# VENC register map
Vendor: Texas Instruments
Peripheral module from a debugger description file (folder DM50x).
Registers are 32-bit, access per field, reset 0x0 unless marked. A register's access mark holds for its fields unless they carry their own. Offsets are as the file gives them; lines under a group give offsets from that group; [hi:lo] are bit positions; {n}, {i} and the like mark numbered series; 'fields as' and 'values as' point back to an identical list; <NAME> marks a mode.

## VENC
0x00 VENC_REV_ID ro reset not defined — Revision ID for the encoder
  [31:0] REVISION — IP Revision
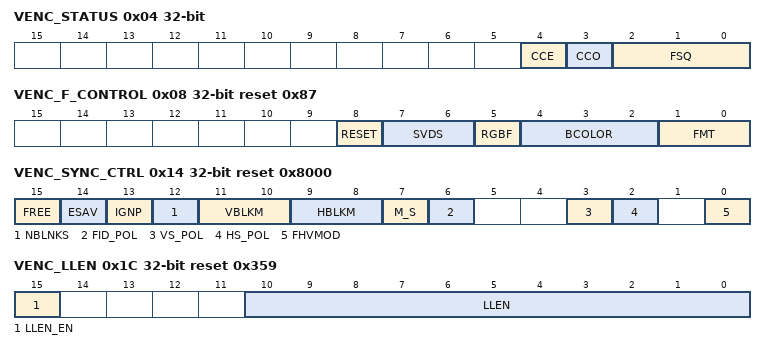
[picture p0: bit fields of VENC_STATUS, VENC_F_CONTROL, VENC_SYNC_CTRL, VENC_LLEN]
0x04 VENC_STATUS ro — STATUS
  [4] CCE — Closed Caption Status for Even Field. This bit is set immediately after the data in registers LINE21_E0 and LINE21_E1 have been encoded to closed caption. This bit is reset when both of these registers are written.
  [3] CCO — Closed Caption Status for Odd Field. This bit is set immediately after the data in registers LINE21_O0 and LINE21_O1 have been encoded to closed caption. This bit is reset when both of these registers are written.
  [2:0] FSQ — Field Sequence ID. For PAL, all three FSQ[2:0] are used whereas for NTSC only FSQ[1:0] is meaningful. Furthermore, FSQ[0] represents ODD field when it is '0' and EVEN field when it is '1'.
    0=ODD_field; 1=EVEN_field
0x08 VENC_F_CONTROL reset 0x87 — This register specifies the input video source and format
  [8] RESET rw — RESET the encoder
    0=No_effect; 1=Reset the encoder, after reset, this bit is automatically set to zero
  [7:6] SVDS rw — Select Video Data Source.
    0=Use_external_video_source; 1=Use_internal_Color_BAR; 2=Use_background_color
  [5] RGBF rw — RGB /YCrCb input coding range
    0=RGB_0 (The input RGB data are in binary format with coding range 0-255 The input YCrCb data are in binary format with coding range 0-255); 1=RGB_ITU-601_1 (The input RGB data are in binary format with coding range 16-235 The input YCrCb data are in binary format conforming to ITU-601 standard)
  [4:2] BCOLOR rw — Background color select
  [1:0] FMT rw — These two bits specify the video input data stream format and timing
    0=24-bit_4:4:4_RGB; 1=24-bit_4:4:4; 2=16-bit_4:2:2; 3=8-bit_ITU-R_656_4:2:2
0x10 VENC_VIDOUT_CTRL — Encoder output clock
  [0] MHZ_27_54 rw
    0=54_MHz,_4x_oversampling; 1=27MHz, 2x oversampling, the last 2x oversampling filter bypassed
0x14 VENC_SYNC_CTRL reset 0x8000 — SYNC Control register
  [15] FREE rw — Free running
    0=Free_running_disabled; 1=HSYNC_VSYNC_1 (Free running enabled. HSYNC and VSYNC are ignored)
  [14] ESAV rw — Enable to detect F and V bits only on EAV in ITU-R 656 input mode
    0=F_V_EAV_SAV_0 (Detection of F and V bits on both EAV and SAV); 1=Detection_of_F_and_V_bits_only_on_EAV
  [13] IGNP rw — Ignore protection bits in ITU-R 656 input mode
    0=Protection_bits_are_not_ignored; 1=Protection_bits_are_ignored
  [12] NBLNKS rw — Blank shaping
    0=Blank_shaping_enabled; 1=Blank_shaping_disabled
  [11:10] VBLKM rw — Vertical blanking mode
    0=Internal_default_blanking; 1=AND_FAL_LAL_1 (Internal default blanking AND internal programmable blanking defined by FAL and LAL)
  [9:8] HBLKM rw — Horizontal blanking mode
    0=Internal_default_blanking; 1=SAVID_EAVID_1 (Internal programmable blanking defined by SAVID and EAVID); 2=External_blanking_defined_by_AVID
  [7] M_S rw — Encoder is master or slave of external sync
    0=FID_AVID._0 (Sync master. Encoder outputs Vsync, Hsync, FID and AVID.); 1=FID_AVID._1 (Sync slave. Encoder is synchronized to external Vsync, Hsync, FID and AVID.)
  [6] FID_POL rw — FID output polarity
    0=ODD_field_=_'0'_EVEN_field_=_'1'; 1=ODD_field_=_'1'_EVEN_field_=_'0'
  [3] VS_POL rw — VS input polarity
    0=VS_is_active_high; 1=VS_is_active_low
  [2] HS_POL rw — HS input polarity
    0=HS_is_active_high; 1=HS_is_active_low
  [0] FHVMOD rw — FID extracted from external FID or HSYNC and VSYNC
    0=External_FID; 1=Extracted_from_HSYNC_and_VSYNC
0x1C VENC_LLEN reset 0x359 — LLEN
  [15] LLEN_EN rw
    0=disable; 1=enable
  [10:0] LLEN rw — LLEN[10:0] Line length or total number of pixels in a scan line including active video and blanking. Total number of pixels in a scan line = LLEN NOTE: A write to bit 11 of this bit field is illegal.
0x20 VENC_FLENS reset 0x20C — FLENS
  [10:0] FLENS rw — The frame length or total number of lines in a frame including active video and blanking from the source image. Total number of lines in a frame from the source image = FLENS + 1
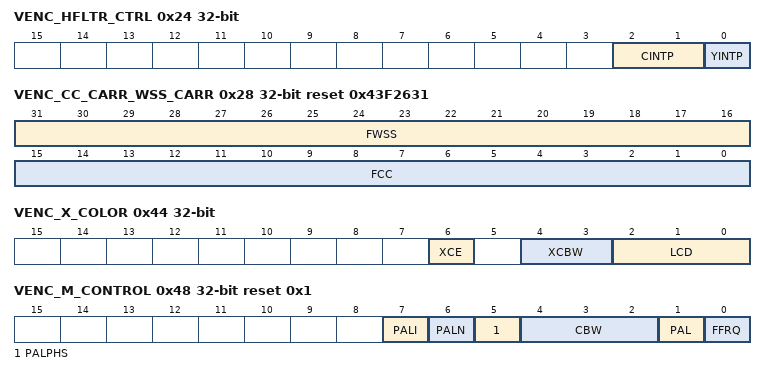
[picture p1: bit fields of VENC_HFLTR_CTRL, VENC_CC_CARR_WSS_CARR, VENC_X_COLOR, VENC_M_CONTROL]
0x24 VENC_HFLTR_CTRL — HFLTR_CTRL
  [2:1] CINTP rw — Chrominance interpolation filter control
    0=The chrominance interpolation filter is enabled; 1=The first section of the chrominance interpolation filter is bypassed; 2=The second section of the chrominance interpolation filter is bypassed; 3=Both sections of the filter are bypassed
  [0] YINTP rw — Luminance interpolation filter control
    0=The luminance interpolation filter is enabled; 1=The luminance interpolation filter is bypassed
0x28 VENC_CC_CARR_WSS_CARR rw reset 0x43F2631 — Frequencie code control
  [31:16] FWSS — Wide screen signaling run-in code frequency control. For 50-Hz systems, FWSS = 2 * 5 * 10/(LLEN * Fh), where LLEN = total number of pixels in a scan line Fh = line frequency.
  [15:0] FCC — Close caption run-in code frequency control. For 60-Hz system, FCC = 2 * 0.5035 * 10/(LLEN * Fh) For 50-Hz systems, FCC = 2* 0.500 * 10/(LLEN * Fh), where LLEN = total number of pixels in a scan line Fh = line frequency.
0x2C VENC_C_PHASE — C_PHASE
  [7:0] CPHS rw — Phase of the encoded video color subcarrier (including the color burst) relative to H-sync. The adjustable step is 360/256 degrees.
0x30 VENC_GAIN_U reset 0x102 — Gain control for Cb signal
  [8:0] GU rw — Gain control for Cb signal. Following are typical programming examples for NTSC and PAL standards. NTSC with 7.5 IRE pedestal: WHITE - BLACK = 92.5 IRE GU = 0x102 NTSC with no pedestal: WHITE - BLACK = 100 IRE GU = 0x117 PAL with no pedestal: WHITE - BLACK = 100 IRE GU = 0x111
0x34 VENC_GAIN_V reset 0x16C — Gain control of Cr signal
  [8:0] GV rw — Gain control of Cr signal. Following are typical programming examples for NTSC and PAL standards. NTSC with 7.5 IRE pedestal: WHITE - BLACK = 92.5 IRE GV = 0x16C NTSC with no pedestal: WHITE - BLACK = 100 IRE GV = 0x189 PAL with no pedestal: WHITE - BLACK = 100 IRE GV = 0x181
0x38 VENC_GAIN_Y reset 0x12F — Gain control of Y signal
  [8:0] GY rw — Gain control of Y signal. Following are typical programming examples for NTSC/PAL standards. NTSC with 7.5 IRE pedestal: WHITE - BLACK = 92.5 IRE GY = 0x12F NTSC with no pedestal: WHITE - BLACK = 100 IRE GY = 0x147 PAL with no pedestal: WHITE - BLACK = 100 IRE GY = 0x140
0x3C VENC_BLACK_LEVEL reset 0x43 — BLACK LEVEL
  [6:0] BLACK rw — Black level setting. Following are typical programming examples for NTSC/PAL standards. NTSC with 7.5 IRE pedestal: WHITE - BLACK = 92.5 IRE BLACK_LEVEL = 0x43 NTSC with no pedestal: WHITE - BLACK = 100 IRE BLACK_LEVEL = 0x38 PAL with no pedestal: WHITE - BLACK = 100 IRE BLACK_LEVEL = 0x3B
0x40 VENC_BLANK_LEVEL reset 0x38 — BLANK LEVEL
  [6:0] BLANK rw — Blank level setting. Following are typical programming examples for NTSC/PAL standards. NTSC with 7.5 IRE pedestal: WHITE - BLACK = 92.5 IRE BLANK_LEVEL = 0x38 NTSC with no pedestal: WHITE - BLACK = 100 IRE BLANK_LEVEL = 0x38 PAL with no pedestal: WHITE - BLACK = 100 IRE BLANK_LEVEL = 0x3B
0x44 VENC_X_COLOR — Cross-Colour Control register
  [6] XCE rw — Cross color reduction enable for composite video output. Cross color does not affect S-video output
    0=Cross_color_reduction_is_disabled; 1=Cross_color_is_enabled
  [4:3] XCBW rw — Cross color reduction filter selection
    0=The notch is at 32.8 % of the frequency of the encoding pixel clock; 1=The notch is at 26.5 % of the frequency of the encoding pixel clock; 2=The notch is at 30.0 % of the frequency of the encoding pixel clock; 3=The notch is at 29.2 % of the frequency of the encoding pixel clock
  [2:0] LCD rw — These three bits can be used for chroma channel delay compensation. Delay on Luma channel.
    0=0; 1=0.5_pixel_clock_period; 2=1.0_pixel_clock_period; 3=1.5_pixel_clock_period; 4=-2.0_pixel_clock_period; 5=-1.5_pixel_clock_period; 6=-1.0_pixel_clock_period; 7=-0.5_pixel_clock_period
0x48 VENC_M_CONTROL reset 0x1 — M_CONTROL
  [7] PALI rw — PAL I enable
    0=Normal_oeration; 1=PAL_I_Enable
  [6] PALN rw — PAL N Enable
    0=Normal_operation; 1=PAL_N_enable
  [5] PALPHS rw — PAL switch phase setting
    0=PAL_switch_phase_is_nominal; 1=PAL_1 (PAL switch phase is inverted compared to nominal)
  [4:2] CBW rw — Chrominance lowpass filter bandwidth control
    0=-6db at 21.8 % of encoding pixel clock frequency; 1=-6db at 19.8 % of encoding pixel clock frequency; 2=-6db at 18.0 % of encoding pixel clock frequency; 5=-6db at 23.7 % of encoding pixel clock frequency; 6=-6db at 26.8 % of encoding pixel clock frequency; 7=Chrominance_lowpass_filter_bypass
  [1] PAL rw — Phase alternation line encoding selection
    0=Phase alternation line encoding disabled; 1=Phase_alternation_line_encoding_enabled
  [0] FFRQ rw — The value of this field and the SQP bit in the BSTAMP_WSS_DATA register control the number of horizontal pixels displayed per scan line # OF MODE SQP FFRQ PIXEL PER LINE ITU-R 601 NTSC 0 1 858 Square pixel NTSC 1 1 780 ITU-R 601 PAL 0 0 864 Square pixel PAL 1 0 944
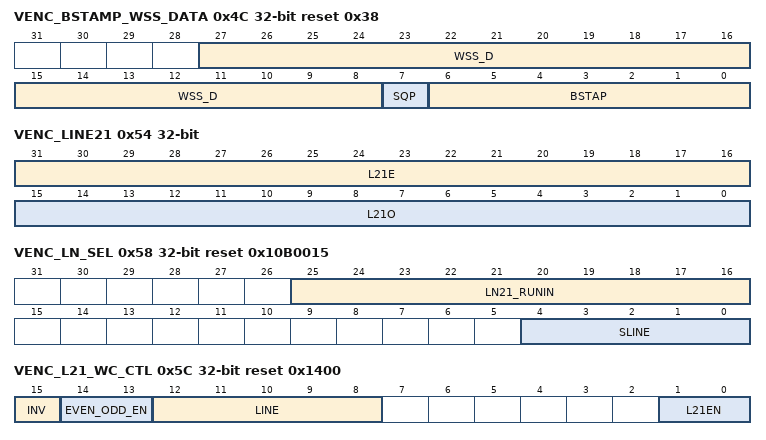
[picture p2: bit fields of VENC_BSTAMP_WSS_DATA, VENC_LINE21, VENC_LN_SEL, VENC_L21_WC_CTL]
0x4C VENC_BSTAMP_WSS_DATA reset 0x38 — BSTAMP and WSS_DATA
  [27:8] WSS_D rw — Wide Screen Signaling data NTSC: WORD 0 D0, D1 WORD 1 D2, D3, D4, D5 WORD 2 D6, D7, D8, D9, D10, D11, D12, D13 CRC D14, D15, D16, D17, D18, D19 PAL: GROUP A D0, D1, D2, D3 GROUP B D4, D5, D6, D7 GROUP C D8, D9 ,D10 GROUP D D11, D12, D13
  [7] SQP rw — Square-pixel sampling rate. See FFRQ in M_CONTROL register for programming information.
    0=ITU-R_601_sampling_rate; 1=Square-pixel_sampling_rate
  [6:0] BSTAP rw — Setting of amplitude of color burst.
0x50 VENC_S_CARR rw reset 0x21F07C1F — Color Subcarrier Frequency Registers.
  [31:0] FSC — These four bytes' data are used to program color subcarrier frequency. These four bytes are determined by the following formula. S_CARR = ROUND((Fsc/Fclkenc) * 232) Where Fsc = Frequency of the subcarrier Fclkenc = Frequency of the internal video encoding clock = 2*LLEN *Fh LLEN = Number of pixels in a scan line Fh = Line frequency See the description of LLEN registers (subaddresses 0x42 and 0x43).
0x54 VENC_LINE21 rw — LINE 21
  [31:16] L21E — The two bytes of the closed caption data in the even field.For the data stream content, see. . [31:24] First byte of data . [23:16] Second byte of data .
  [15:0] L21O — The two bytes of the closed caption data in the odd fieldFor the data stream content, see. . [15:8] First byte of data . [7:0] Second byte of data .
0x58 VENC_LN_SEL reset 0x10B0015 — LN_SEL
  [25:16] LN21_RUNIN rw — The two Bytes of the closed caption runin code position from the HSYNC
  [4:0] SLINE rw — Selects the line where closed caption or extended service data are encoded.PAL mode: Because there is a one-line offset, program the desired line number – 1. . NTSC mode: Because there is a four-line offset, program the desired line number – 4. .
0x5C VENC_L21_WC_CTL reset 0x1400 — L21 and WC_CTL registers
  [15] INV rw — WSS inverter
    0=no_effect; 1=invert_WSS_data
  [14:13] EVEN_ODD_EN rw — This bit controls the WSS encoding.
    0=WSS_encoding_OFF; 1=Enables encoding in 2nd field (odd field); 2=Enables encoding in 1st field (even field); 3=Enables_encoding_in_both_fields
  [12:8] LINE rw — Selects the line where WSS data are encoded.PAL mode: Because there is a one-line offset, program the desired line number – 1. . NTSC mode: Because there is a four-line offset, program the desired line number – 4. .
  [1:0] L21EN rw — Those bits controls the Line21 closed caption encoding according to the mode.
    0=Line21_encoding_OFF; 1=(ODD_1 (Enables encoding in 1st field (ODD field)); 2=(EVEN_2 (Enables encoding in 2d field (EVEN field)); 3=Enables_encoding_in_both_fields
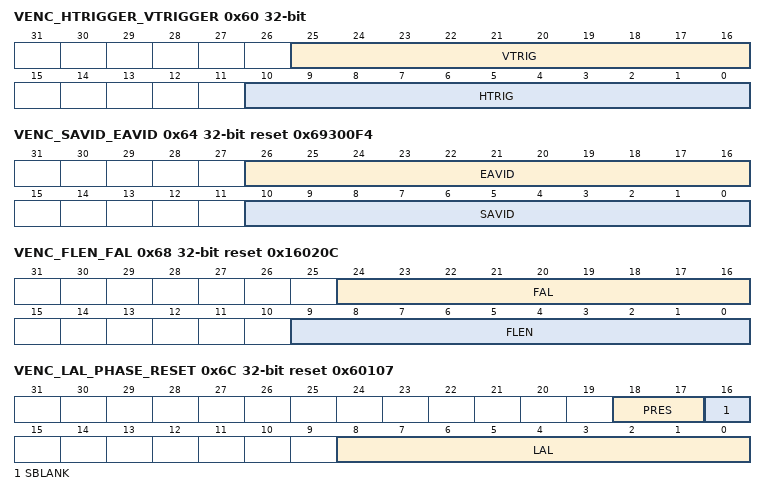
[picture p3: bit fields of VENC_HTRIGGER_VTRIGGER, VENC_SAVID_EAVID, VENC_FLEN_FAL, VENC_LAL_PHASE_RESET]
0x60 VENC_HTRIGGER_VTRIGGER — HTRIGGER and VTRIGGER
  [25:16] VTRIG rw — Vertical trigger reference for VSYNC. These bits specify the phase between VSYNC input and the lines in a field. The VTRIG field is expressed in units of half-line.
  [10:0] HTRIG rw — Horizontal trigger phase, which sets HSYNC. HTRIG is expressed in half-pixels or clk2x (27 MHz) periods
0x64 VENC_SAVID_EAVID reset 0x69300F4 — SAVID and EAVID
  [26:16] EAVID rw — End of active video. These bits define the ending pixel position on a horizontal display line where active video will be displayed.
  [10:0] SAVID rw — Start of active video. These bits define the starting pixel position on a horizontal line where active video will be displayed.
0x68 VENC_FLEN_FAL reset 0x16020C — FLEN and FAL
  [24:16] FAL rw — First Active Line of Field. These bits define the first active line of a field
  [9:0] FLEN rw — Field length. These bits define the number of half_lines in each field. Length of field = (FLEN + 1) half_lines
0x6C VENC_LAL_PHASE_RESET reset 0x60107 — LAL and PHASE_RESET
  [18:17] PRES rw — Phase reset mode.
    0=No_reset; 1=Reset_every_two_lines; 2=5A)_2 (Reset every eight fields. Color subcarrier phase is reset to C_Phase (subaddress 5A) upon reset); 3=5A)_3 (Reset every four fields. Color subcarrier phase is reset to C_Phase (subaddress 5A) upon reset)
  [16] SBLANK rw — Vertical blanking setting
    0=FAL_LAL_0 (Vertical blanking is defined by the setting of FAL and LAL registers.); 1=Vertical blanking is forced automatically during field synchronization and equalization
  [8:0] LAL rw — Last Active Line of Field. These bits define the last active line of a field
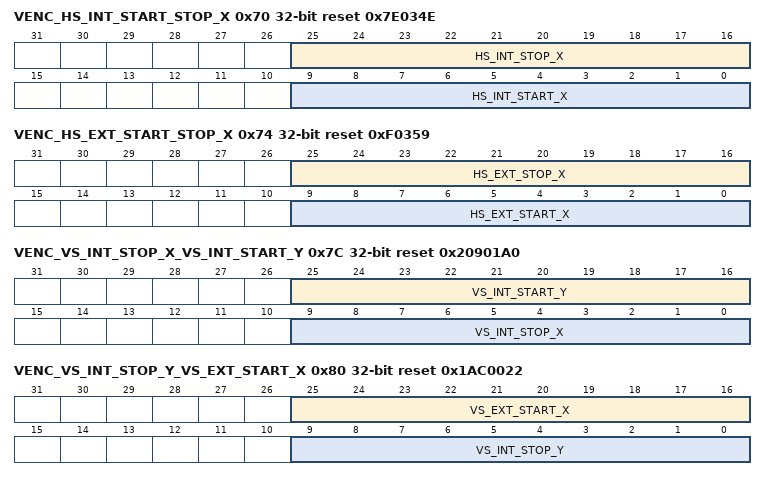
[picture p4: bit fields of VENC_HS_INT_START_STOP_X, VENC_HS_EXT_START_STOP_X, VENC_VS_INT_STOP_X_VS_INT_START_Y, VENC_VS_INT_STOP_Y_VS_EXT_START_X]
0x70 VENC_HS_INT_START_STOP_X reset 0x7E034E — HS_INT_START_STOP_X
  [25:16] HS_INT_STOP_X rw — HSYNC internal stop. These bits define HSYNC internal stop pixel value
  [9:0] HS_INT_START_X rw — HSYNC internal start. These bits define HSYNC internal start pixel value
0x74 VENC_HS_EXT_START_STOP_X reset 0xF0359 — HS_EXT_START_STOP_X
  [25:16] HS_EXT_STOP_X rw — HSYNC external stop. These bits define HSYNC external stop pixel value
  [9:0] HS_EXT_START_X rw — HSYNC external start. These bits define HSYNC external start pixel value
0x78 VENC_VS_INT_START_X reset 0x1A00000 — VS_INT_START_X
  [25:16] VS_INT_START_X rw — VSYNC internal start. These bits define VSYNC internal start pixel value.
0x7C VENC_VS_INT_STOP_X_VS_INT_START_Y reset 0x20901A0 — VS_INT_STOP_X and VS_INT_START_Y
  [25:16] VS_INT_START_Y rw — VSYNC internal start. These bits define VSYNC internal start line value
  [9:0] VS_INT_STOP_X rw — VSYNC internal stop. These bits define VSYNC internal stop pixel value
0x80 VENC_VS_INT_STOP_Y_VS_EXT_START_X reset 0x1AC0022 — VS_INT_STOP_Y and VS_EXT_START_X
  [25:16] VS_EXT_START_X rw — VSYNC external start. These bits define VSYNC external start pixel value.
  [9:0] VS_INT_STOP_Y rw — VSYNC internal stop. These bits define VSYNC internal stop line value.
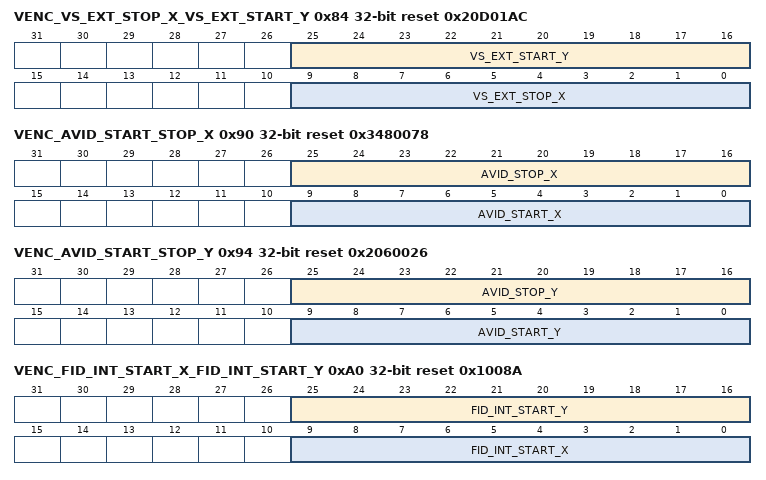
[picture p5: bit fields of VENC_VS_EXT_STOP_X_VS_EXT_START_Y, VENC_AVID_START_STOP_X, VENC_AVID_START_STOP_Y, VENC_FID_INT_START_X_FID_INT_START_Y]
0x84 VENC_VS_EXT_STOP_X_VS_EXT_START_Y reset 0x20D01AC — VS_EXT_STOP_X and VS_EXT_START_Y
  [25:16] VS_EXT_START_Y rw — VSYNC external start. These bits define VSYNC external start line value.
  [9:0] VS_EXT_STOP_X rw — VSYNC external stop. These bits define VSYNC external stop pixel value.
0x88 VENC_VS_EXT_STOP_Y reset 0x6 — VS_EXT_STOP_Y
  [9:0] VS_EXT_STOP_Y rw — VSYNC external stop. These bits define VSYNC external stop line value.
0x90 VENC_AVID_START_STOP_X reset 0x3480078 — AVID_START_STOP_X
  [25:16] AVID_STOP_X rw — AVID stop. These bits define AVID stop pixel value
  [9:0] AVID_START_X rw — AVID start. These bits define AVID start pixel value
0x94 VENC_AVID_START_STOP_Y reset 0x2060026 — AVID_START_STOP_Y
  [25:16] AVID_STOP_Y rw — AVID stop. These bits define AVID stop line value.
  [9:0] AVID_START_Y rw — AVID start. These bits define AVID start line value
0xA0 VENC_FID_INT_START_X_FID_INT_START_Y reset 0x1008A — FID_INT_START_X and FID_INT_START_Y
  [25:16] FID_INT_START_Y rw — FID internal stop. These bits define FID internal start line value
  [9:0] FID_INT_START_X rw — FID internal start. These bits define FID internal start pixel value
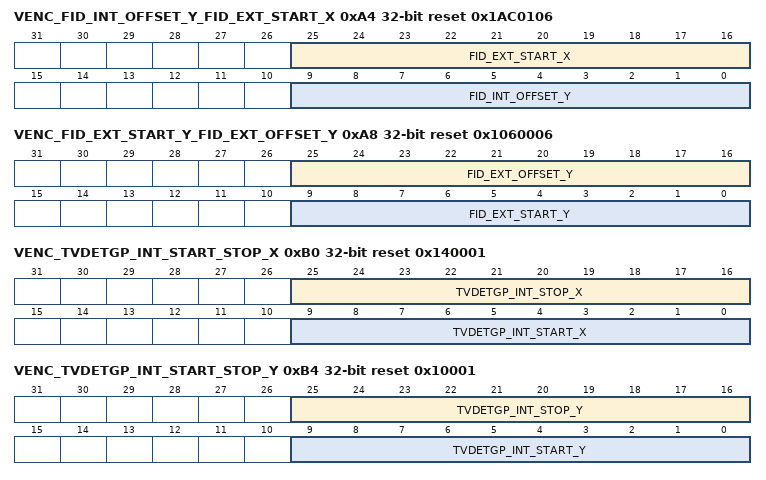
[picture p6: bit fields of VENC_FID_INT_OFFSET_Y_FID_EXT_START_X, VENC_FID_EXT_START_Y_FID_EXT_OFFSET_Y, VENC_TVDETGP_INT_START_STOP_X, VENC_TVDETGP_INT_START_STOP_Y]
0xA4 VENC_FID_INT_OFFSET_Y_FID_EXT_START_X reset 0x1AC0106 — FID_INT_OFFSET_Y and FID_EXT_START_X
  [25:16] FID_EXT_START_X rw — FID external start. These bits define FID external start pixel value
  [9:0] FID_INT_OFFSET_Y rw — FID internal offset. These bits define FID internal offset linel value
0xA8 VENC_FID_EXT_START_Y_FID_EXT_OFFSET_Y reset 0x1060006 — FID_EXT_START_Y and FID_EXT_OFFSET_Y
  [25:16] FID_EXT_OFFSET_Y rw — FID external offset. These bits define FID external offset line value
  [9:0] FID_EXT_START_Y rw — FID external start. These bits define FID external start line value.
0xB0 VENC_TVDETGP_INT_START_STOP_X reset 0x140001 — TVDETGP_INT_START_STOP_X
  [25:16] TVDETGP_INT_STOP_X rw — TVDETGP internal stop. These bits define TVDETGP internal stop pixel value.
  [9:0] TVDETGP_INT_START_X rw — TVDETGP internal start. These bits define TVDETGP internal start pixel value
0xB4 VENC_TVDETGP_INT_START_STOP_Y reset 0x10001 — TVDETGP_INT_START_STOP_Y
  [25:16] TVDETGP_INT_STOP_Y rw — TVDETGP internal stop. These bits define TVDETGP internal stop line value.
  [9:0] TVDETGP_INT_START_Y rw — TVDETGP internal start. These bits define TVDETGP internal start line value
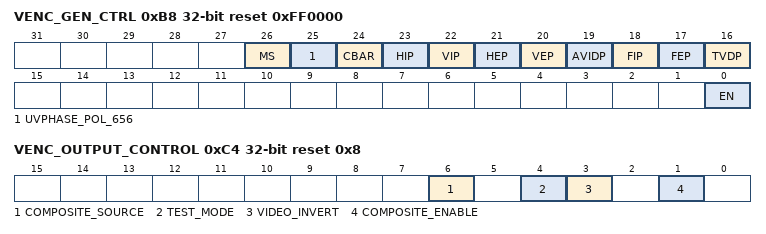
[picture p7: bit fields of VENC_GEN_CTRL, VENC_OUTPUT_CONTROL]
0xB8 VENC_GEN_CTRL reset 0xFF0000 — TVDETGP enable and SYNC_POLARITY and UVPHASE_POL
  [26] MS rw — UVPHASE_POL MS mode UV phase
    0=CbCr; 1=CrCb
  [25] UVPHASE_POL_656 rw — UVPHASE_POL 656 input mode UV phase
    0=CbCr; 1=CrCb
  [24] CBAR rw — UVPHASE_POL CBAR mode UV phase
    0=CbCr; 1=CrCb
  [23] HIP rw — HSYNC internal polarity
    0=Active_Low; 1=Active_High
  [22] VIP rw — VSYNC internal polarity
    0=Active_Low; 1=Active_High
  [21] HEP rw — HSYNC external polarity
    0=Active_Low; 1=Active_High
  [20] VEP rw — VSYNC externall polarity
    0=Active_Low; 1=Active_High
  [19] AVIDP rw — AVID polarity
    0=Active_Low; 1=Active_High
  [18] FIP rw — FID internal polarity
    0=Active_Low; 1=Active_High
  [17] FEP rw — FID external polarity
    0=Active_Low; 1=Active_High
  [16] TVDP rw — TVDETGP polarity
    0=Active_Low; 1=Active_High
  [0] EN rw — TVDETGP generation enable
    0=Disabled; 1=Enabled
0xC4 VENC_OUTPUT_CONTROL reset 0x8 — Output channel control register Also contains some test control features
  [6] COMPOSITE_SOURCE rw — Source of composite video data in test mode
    0=OUTPUT_TEST[9:0]_0 (Composite test data comes from internal register OUTPUT_TEST[9:0]); 1=G[1:0],_B[7:0]_1 (Composite test data comes from display controller video port G[1:0], B[7:0])
  [4] TEST_MODE rw — This enables the video DACs to be tested. The values sent to the DACs comes from a register for each output channel (Luma, Composite or Chroma) or from the display controller video port bits G[1:0], B[7:0], depending on the setting of the Source bits
    0=Video_outputs_are_in_normal_operation; 1=Test mode. Video outputs are directly connected to either internal registers or the display controller video port.
  [3] VIDEO_INVERT rw — Controls the video output polarity. This may be used to correct for inversion in an external video amplifier.
    0=Video_outputs_are_inverted; 1=Video_outputs_are_normal_polarity
  [1] COMPOSITE_ENABLE rw — Enable the Composite output channel
    0=Composite_output_is_disabled; 1=Composite_output_is_enabled
0xC8 VENC_OUTPUT_TEST — Test values for the Luma/Composite Video DAC
  [9:0] COMPOSITE_TEST rw — In test mode, DAC input value (if composite video is selected)
